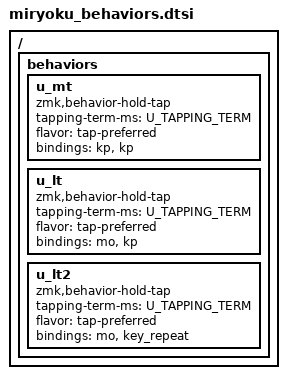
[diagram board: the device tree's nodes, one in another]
// Copyright 2022 Manna Harbour
// https://github.com/manna-harbour/miryoku

/ {
  behaviors {
    u_mt: u_mt {
      compatible = "zmk,behavior-hold-tap";
      #binding-cells = <2>;
      tapping-term-ms = <U_TAPPING_TERM>;
      flavor = "tap-preferred";
      bindings = <&kp>, <&kp>;
    };
    u_lt: u_lt {
      compatible = "zmk,behavior-hold-tap";
      #binding-cells = <2>;
      tapping-term-ms = <U_TAPPING_TERM>;
      flavor = "tap-preferred";
      bindings = <&mo>, <&kp>;
    };
    u_lt2: u_lt2 {
      compatible = "zmk,behavior-hold-tap";
      #binding-cells = <2>;
      tapping-term-ms = <U_TAPPING_TERM>;
      flavor = "tap-preferred";
      bindings = <&mo>, <&key_repeat>;
    };
  };
};

/// {
//    behaviors {
//        key_repeat: key_repeat {
//            compatible = "zmk,behavior-key-repeat";
//            label = "KEY_REPEAT";
//        };
//    };
//};

